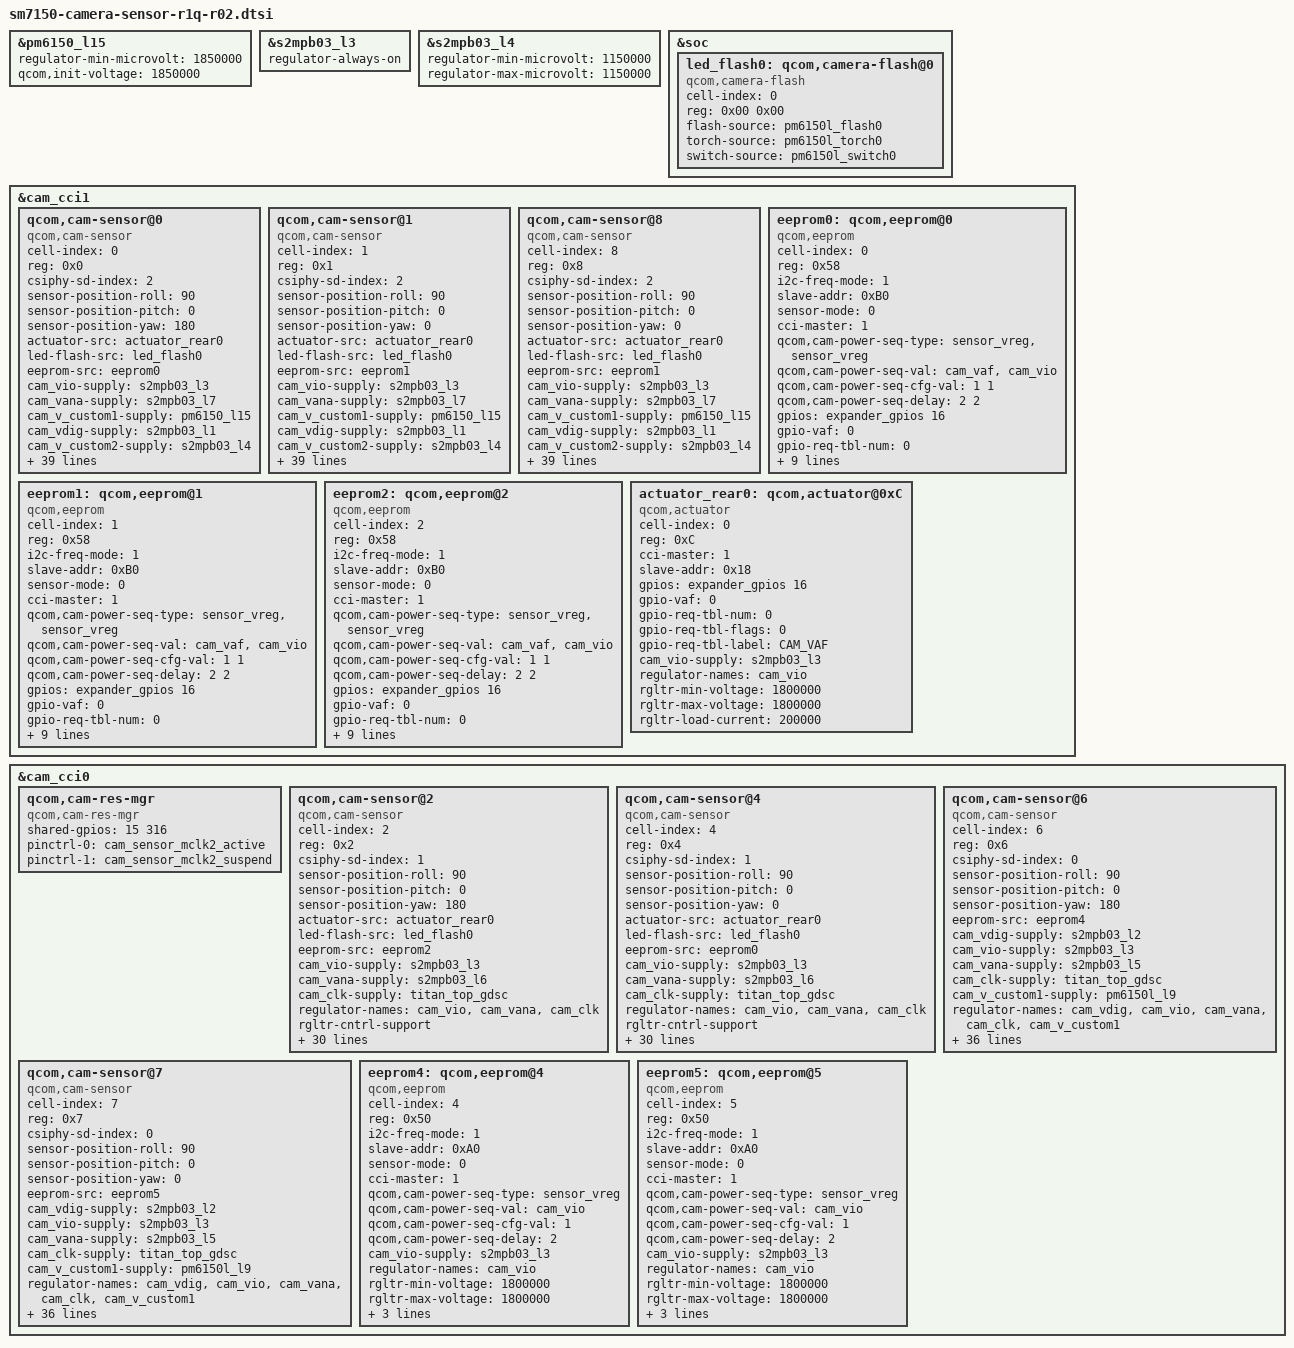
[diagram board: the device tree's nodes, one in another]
/*
 * Copyright (c) 2018, The Linux Foundation. All rights reserved.
 *
 * This program is free software; you can redistribute it and/or modify
 * it under the terms of the GNU General Public License version 2 and
 * only version 2 as published by the Free Software Foundation.
 *
 * This program is distributed in the hope that it will be useful,
 * but WITHOUT ANY WARRANTY; without even the implied warranty of
 * MERCHANTABILITY or FITNESS FOR A PARTICULAR PURPOSE.  See the
 * GNU General Public License for more details.
 */

&pm6150_l15 {
    regulator-min-microvolt = <1850000>;
    qcom,init-voltage = <1850000>;
};

&s2mpb03_l3 {
    regulator-always-on;
};

&s2mpb03_l4 {
    regulator-min-microvolt = <1150000>;
    regulator-max-microvolt = <1150000>;
};

&soc {
        led_flash0: qcom,camera-flash@0 {
              cell-index = <0>;
              reg = <0x00 0x00>;
              compatible = "qcom,camera-flash";
              flash-source = <&pm6150l_flash0>;
              torch-source = <&pm6150l_torch0>;
              switch-source = <&pm6150l_switch0>;		
              status = "ok";
        };
};

&cam_cci1 {
	qcom,cam-sensor@0 {
		cell-index = <0>;
		compatible = "qcom,cam-sensor";
		reg = <0x0>;
		csiphy-sd-index = <2>;
		sensor-position-roll = <90>;
		sensor-position-pitch = <0>;
		sensor-position-yaw = <180>;
		actuator-src = <&actuator_rear0>;
		led-flash-src = <&led_flash0>;
		eeprom-src = <&eeprom0>;

		// LDO
		cam_vio-supply = <&s2mpb03_l3>;
		cam_vana-supply = <&s2mpb03_l7>;
		cam_v_custom1-supply = <&pm6150_l15>;	// Analog 1.85
		cam_vdig-supply = <&s2mpb03_l1>;
		cam_v_custom2-supply = <&s2mpb03_l4>;	// Digital PLL 1.15
		cam_clk-supply = <&titan_top_gdsc>;
		regulator-names = "cam_vio", "cam_vana", "cam_v_custom1", "cam_vdig", "cam_v_custom2", "cam_clk";
		rgltr-cntrl-support;
		rgltr-min-voltage = <1800000 2900000 1850000 1100000 1150000 0>;
		rgltr-max-voltage = <1800000 2900000 1850000 1100000 1150000 0>;
		rgltr-load-current = <200000 200000 200000 200000 200000 0>;

		// GPIO
		gpio-no-mux = <0>;
		pinctrl-names = "cam_default", "cam_suspend";
		pinctrl-0 = <&cam_sensor_rear1_active>;
		pinctrl-1 = <&cam_sensor_rear1_suspend>;
		gpios = <&tlmm 15 0>,
			<&tlmm 33 0>,
			<&expander_gpios 16 0>;
		gpio-reset = <1>;
		gpio-vaf = <2>;
		gpio-req-tbl-num = <0 1 2>;
		gpio-req-tbl-flags = <1 0 0>;
		gpio-req-tbl-label = "CAMIF_MCLK2", "CAM_RESET1", "CAM_VAF";
		use-shared-clk;

		sensor-mode = <0>;
		cci-device = <1>;
		cci-master = <0>;
		status = "ok";
		clocks = <&clock_camcc CAM_CC_MCLK2_CLK>;
		clock-names = "cam_clk";
		clock-cntl-level = "turbo";
		clock-rates = <24000000>;
		cam,isp = <0>;                  // 0 : INT , 1 : EXT , 2 : SOC
		cam,cal_memory = <2>;           // 0 : N , 1 : FROM , 2 : EEPROM , 3 : OTP
		cam,read_version = <0>;         // 0 : SYSFS , 1 : CAMON
		cam,core_voltage = <0>;         // 0 : N , 1 : Y
		cam,upgrade = <0>;              // 0 : N , 1 : SYSFS , 2 : CAMON
		cam,fw_write = <0>;             // 0 : N , 1 : OS , 2 : SD , 3 : ALL
		cam,fw_dump = <0>;              // 0 : N , 1 : Y
		cam,companion_chip = <0>;       // 0 : N , 1 : Y
		cam,ois = <0>;                  // 0 : N , 1 : Y
		cam,dual_open = <0>;            // 0 : N , 1 : Y
		cam,valid = <1>;                // 0 : N , 1 : Y
	};

	qcom,cam-sensor@1 {
		cell-index = <1>;
		compatible = "qcom,cam-sensor";
		reg = <0x1>;
		csiphy-sd-index = <2>;
		sensor-position-roll = <90>;
		sensor-position-pitch = <0>;
		sensor-position-yaw = <0>;
		actuator-src = <&actuator_rear0>;
		led-flash-src = <&led_flash0>;
		eeprom-src = <&eeprom1>;

		// LDO
		cam_vio-supply = <&s2mpb03_l3>;
		cam_vana-supply = <&s2mpb03_l7>;
		cam_v_custom1-supply = <&pm6150_l15>;	// Analog 1.85
		cam_vdig-supply = <&s2mpb03_l1>;
		cam_v_custom2-supply = <&s2mpb03_l4>;	// Digital PLL 1.15
		cam_clk-supply = <&titan_top_gdsc>;
		regulator-names = "cam_vio", "cam_vana", "cam_v_custom1", "cam_vdig", "cam_v_custom2", "cam_clk";
		rgltr-cntrl-support;
		rgltr-min-voltage = <1800000 2900000 1850000 1100000 1150000 0>;
		rgltr-max-voltage = <1800000 2900000 1850000 1100000 1150000 0>;
		rgltr-load-current = <200000 200000 200000 200000 200000 0>;

		// GPIO
		gpio-no-mux = <0>;
		pinctrl-names = "cam_default", "cam_suspend";
		pinctrl-0 = <&cam_sensor_rear1_active>;
		pinctrl-1 = <&cam_sensor_rear1_suspend>;
		gpios = <&tlmm 15 0>,
			<&tlmm 33 0>,
			<&expander_gpios 16 0>;
		gpio-reset = <1>;
		gpio-vaf = <2>;
		gpio-req-tbl-num = <0 1 2>;
		gpio-req-tbl-flags = <1 0 0>;
		gpio-req-tbl-label = "CAMIF_MCLK2", "CAM_RESET1", "CAM_VAF";
		use-shared-clk;

		sensor-mode = <0>;
		cci-device = <1>;
		cci-master = <0>;
		status = "ok";
		clocks = <&clock_camcc CAM_CC_MCLK2_CLK>;
		clock-names = "cam_clk";
		clock-cntl-level = "turbo";
		clock-rates = <24000000>;
		cam,isp = <0>;                  // 0 : INT , 1 : EXT , 2 : SOC
		cam,cal_memory = <2>;           // 0 : N , 1 : FROM , 2 : EEPROM , 3 : OTP
		cam,read_version = <0>;         // 0 : SYSFS , 1 : CAMON
		cam,core_voltage = <0>;         // 0 : N , 1 : Y
		cam,upgrade = <0>;              // 0 : N , 1 : SYSFS , 2 : CAMON
		cam,fw_write = <0>;             // 0 : N , 1 : OS , 2 : SD , 3 : ALL
		cam,fw_dump = <0>;              // 0 : N , 1 : Y
		cam,companion_chip = <0>;       // 0 : N , 1 : Y
		cam,ois = <0>;                  // 0 : N , 1 : Y
		cam,dual_open = <0>;            // 0 : N , 1 : Y
		cam,valid = <1>;                // 0 : N , 1 : Y
	};

	qcom,cam-sensor@8 {
		cell-index = <8>;
		compatible = "qcom,cam-sensor";
		reg = <0x8>;
		csiphy-sd-index = <2>;
		sensor-position-roll = <90>;
		sensor-position-pitch = <0>;
		sensor-position-yaw = <0>;
		actuator-src = <&actuator_rear0>;
		led-flash-src = <&led_flash0>;
		eeprom-src = <&eeprom1>;

		// LDO
		cam_vio-supply = <&s2mpb03_l3>;
		cam_vana-supply = <&s2mpb03_l7>;
		cam_v_custom1-supply = <&pm6150_l15>;	// Analog 1.85
		cam_vdig-supply = <&s2mpb03_l1>;
		cam_v_custom2-supply = <&s2mpb03_l4>;	// Digital PLL 1.15
		cam_clk-supply = <&titan_top_gdsc>;
		regulator-names = "cam_vio", "cam_vana", "cam_v_custom1", "cam_vdig", "cam_v_custom2", "cam_clk";
		rgltr-cntrl-support;
		rgltr-min-voltage = <1800000 2900000 1850000 1100000 1150000 0>;
		rgltr-max-voltage = <1800000 2900000 1850000 1100000 1150000 0>;
		rgltr-load-current = <200000 200000 200000 200000 200000 0>;

		// GPIO
		gpio-no-mux = <0>;
		pinctrl-names = "cam_default", "cam_suspend";
		pinctrl-0 = <&cam_sensor_rear1_active>;
		pinctrl-1 = <&cam_sensor_rear1_suspend>;
		gpios = <&tlmm 15 0>,
			<&tlmm 33 0>,
			<&expander_gpios 16 0>;
		gpio-reset = <1>;
		gpio-vaf = <2>;
		gpio-req-tbl-num = <0 1 2>;
		gpio-req-tbl-flags = <1 0 0>;
		gpio-req-tbl-label = "CAMIF_MCLK2", "CAM_RESET1", "CAM_VAF";
		use-shared-clk;

		sensor-mode = <0>;
		cci-device = <1>;
		cci-master = <0>;
		status = "ok";
		clocks = <&clock_camcc CAM_CC_MCLK2_CLK>;
		clock-names = "cam_clk";
		clock-cntl-level = "turbo";
		clock-rates = <24000000>;
		cam,isp = <0>;                  // 0 : INT , 1 : EXT , 2 : SOC
		cam,cal_memory = <2>;           // 0 : N , 1 : FROM , 2 : EEPROM , 3 : OTP
		cam,read_version = <0>;         // 0 : SYSFS , 1 : CAMON
		cam,core_voltage = <0>;         // 0 : N , 1 : Y
		cam,upgrade = <0>;              // 0 : N , 1 : SYSFS , 2 : CAMON
		cam,fw_write = <0>;             // 0 : N , 1 : OS , 2 : SD , 3 : ALL
		cam,fw_dump = <0>;              // 0 : N , 1 : Y
		cam,companion_chip = <0>;       // 0 : N , 1 : Y
		cam,ois = <0>;                  // 0 : N , 1 : Y
		cam,dual_open = <0>;            // 0 : N , 1 : Y
		cam,valid = <1>;                // 0 : N , 1 : Y
	};
	
	eeprom0: qcom,eeprom@0 {
		cell-index = <0>;
		reg = <0x58>; //QUP use 0xB0
        	compatible = "qcom,eeprom";
        	i2c-freq-mode = <1>;
        	slave-addr = <0xB0>;
        	sensor-mode = <0>;
        	cci-master = <1>;

        	qcom,cam-power-seq-type = "sensor_vreg", "sensor_vreg";
        	qcom,cam-power-seq-val = "cam_vaf", "cam_vio";
        	qcom,cam-power-seq-cfg-val = <1 1>;
        	qcom,cam-power-seq-delay = <2 2>;

		gpios = <&expander_gpios 16 0>;
		gpio-vaf = <0>;
		gpio-req-tbl-num = <0>;
		gpio-req-tbl-flags = <0>;
		gpio-req-tbl-label = "CAM_VAF";

        	cam_vio-supply = <&s2mpb03_l3>;
        	regulator-names = "cam_vio";
		rgltr-min-voltage = <1800000>;
		rgltr-max-voltage = <1800000>;
			rgltr-load-current = <200000>;

			sensor-position = <0>;
			rgltr-cntrl-support;
		};

	eeprom1: qcom,eeprom@1 {
		cell-index = <1>;
		reg = <0x58>; //QUP use 0xB0
        	compatible = "qcom,eeprom";
        	i2c-freq-mode = <1>;
        	slave-addr = <0xB0>;
        	sensor-mode = <0>;
        	cci-master = <1>;

        	qcom,cam-power-seq-type = "sensor_vreg", "sensor_vreg";
        	qcom,cam-power-seq-val = "cam_vaf", "cam_vio";
        	qcom,cam-power-seq-cfg-val = <1 1>;
        	qcom,cam-power-seq-delay = <2 2>;

		gpios = <&expander_gpios 16 0>;
		gpio-vaf = <0>;
		gpio-req-tbl-num = <0>;
		gpio-req-tbl-flags = <0>;
		gpio-req-tbl-label = "CAM_VAF";

        	cam_vio-supply = <&s2mpb03_l3>;
        	regulator-names = "cam_vio";
		rgltr-min-voltage = <1800000>;
		rgltr-max-voltage = <1800000>;
		rgltr-load-current = <200000>;

		sensor-position = <0>;
		rgltr-cntrl-support;
	};

	eeprom2: qcom,eeprom@2 {
		cell-index = <2>;
		reg = <0x58>; //QUP use 0xB0
        	compatible = "qcom,eeprom";
        	i2c-freq-mode = <1>;
        	slave-addr = <0xB0>;
        	sensor-mode = <0>;
        	cci-master = <1>;

        	qcom,cam-power-seq-type = "sensor_vreg", "sensor_vreg";
        	qcom,cam-power-seq-val = "cam_vaf", "cam_vio";
        	qcom,cam-power-seq-cfg-val = <1 1>;
        	qcom,cam-power-seq-delay = <2 2>;

		gpios = <&expander_gpios 16 0>;
		gpio-vaf = <0>;
		gpio-req-tbl-num = <0>;
		gpio-req-tbl-flags = <0>;
		gpio-req-tbl-label = "CAM_VAF";

        	cam_vio-supply = <&s2mpb03_l3>;
        	regulator-names = "cam_vio";
		rgltr-min-voltage = <1800000>;
		rgltr-max-voltage = <1800000>;
		rgltr-load-current = <200000>;

		sensor-position = <0>;
		rgltr-cntrl-support;
	};

	actuator_rear0: qcom,actuator@0xC {
        	cell-index = <0>;
        	reg = <0xC>;
        	cci-master = <1>;
        	slave-addr = <0x18>;
        	compatible = "qcom,actuator";
        
		gpios = <&expander_gpios 16 0>;
		gpio-vaf = <0>;
		gpio-req-tbl-num = <0>;
		gpio-req-tbl-flags = <0>;
		gpio-req-tbl-label = "CAM_VAF";

        	cam_vio-supply = <&s2mpb03_l3>;
        	regulator-names = "cam_vio";
        	rgltr-min-voltage = <1800000>;
        	rgltr-max-voltage = <1800000>;
        	rgltr-load-current = <200000>;
	};
};

&cam_cci0 {
	qcom,cam-res-mgr {
		compatible = "qcom,cam-res-mgr";
		shared-gpios = <15 316>;
		pinctrl-names = "cam_res_mgr_default", "cam_res_mgr_suspend";
		status = "ok";
		pinctrl-0 = <&cam_sensor_mclk2_active>;
		pinctrl-1 = <&cam_sensor_mclk2_suspend>;
	};
	qcom,cam-sensor@2 {
		cell-index = <2>;
		compatible = "qcom,cam-sensor";
		reg = <0x2>;
		csiphy-sd-index = <1>;
		sensor-position-roll = <90>;
		sensor-position-pitch = <0>;
		sensor-position-yaw = <180>;
		actuator-src = <&actuator_rear0>;
		led-flash-src = <&led_flash0>;
		eeprom-src = <&eeprom2>;
		// LDO
		cam_vio-supply = <&s2mpb03_l3>;
		cam_vana-supply = <&s2mpb03_l6>;
		cam_clk-supply = <&titan_top_gdsc>;
		regulator-names = "cam_vio", "cam_vana", "cam_clk";
		rgltr-cntrl-support;
		rgltr-min-voltage = <1800000 2800000 0>;
		rgltr-max-voltage = <1800000 2800000 0>;
		rgltr-load-current = <200000 200000 0>;

		// GPIO
		gpio-no-mux = <0>;
		pinctrl-names = "cam_default", "cam_suspend";
		pinctrl-0 = <&cam_sensor_rear2_active>;
		pinctrl-1 = <&cam_sensor_rear2_suspend>;
		gpios = <&tlmm 15 0>,
			<&tlmm 67 0>,
			<&expander_gpios 17 0>;
		gpio-reset = <1>;
		gpio-vdig = <2>;
		gpio-req-tbl-num = <0 1 2>;
		gpio-req-tbl-flags = <1 0 0>;
		gpio-req-tbl-label = "CAMIF_MCLK2", "CAM_RESET2", "CAM_VDIG";
		use-shared-clk;

		sensor-mode = <0>;
		cci-master = <0>;
		status = "ok";
		clocks = <&clock_camcc CAM_CC_MCLK2_CLK>;
		clock-names = "cam_clk";
		clock-cntl-level = "turbo";
		clock-rates = <24000000>;

		cam,isp = <0>;                  // 0 : INT , 1 : EXT , 2 : SOC
		cam,cal_memory = <2>;           // 0 : N , 1 : FROM , 2 : EEPROM , 3 : OTP
		cam,read_version = <0>;         // 0 : SYSFS , 1 : CAMON
		cam,core_voltage = <0>;         // 0 : N , 1 : Y
		cam,upgrade = <0>;              // 0 : N , 1 : SYSFS , 2 : CAMON
		cam,fw_write = <0>;             // 0 : N , 1 : OS , 2 : SD , 3 : ALL
		cam,fw_dump = <0>;              // 0 : N , 1 : Y
		cam,companion_chip = <0>;       // 0 : N , 1 : Y
		cam,ois = <0>;                  // 0 : N , 1 : Y
		cam,dual_open = <0>;            // 0 : N , 1 : Y
		cam,valid = <1>;                // 0 : N , 1 : Y
	};
	qcom,cam-sensor@4 {
		cell-index = <4>;
		compatible = "qcom,cam-sensor";
		reg = <0x4>;
		csiphy-sd-index = <1>;
		sensor-position-roll = <90>;
		sensor-position-pitch = <0>;
		sensor-position-yaw = <0>;
		actuator-src = <&actuator_rear0>;
		led-flash-src = <&led_flash0>;
		eeprom-src = <&eeprom0>;
		// LDO
		cam_vio-supply = <&s2mpb03_l3>;
		cam_vana-supply = <&s2mpb03_l6>;
		cam_clk-supply = <&titan_top_gdsc>;
		regulator-names = "cam_vio", "cam_vana", "cam_clk";
		rgltr-cntrl-support;
		rgltr-min-voltage = <1800000 2800000 0>;
		rgltr-max-voltage = <1800000 2800000 0>;
		rgltr-load-current = <200000 200000 0>;

		// GPIO
		gpio-no-mux = <0>;
		pinctrl-names = "cam_default", "cam_suspend";
		pinctrl-0 = <&cam_sensor_rear2_active>;
		pinctrl-1 = <&cam_sensor_rear2_suspend>;
		gpios = <&tlmm 15 0>,
			<&tlmm 67 0>,
			<&expander_gpios 17 0>;
		gpio-reset = <1>;
		gpio-vdig = <2>;
		gpio-req-tbl-num = <0 1 2>;
		gpio-req-tbl-flags = <1 0 0>;
		gpio-req-tbl-label = "CAMIF_MCLK2", "CAM_RESET2", "CAM_VDIG";
		use-shared-clk;

		sensor-mode = <0>;
		cci-master = <0>;
		status = "ok";
		clocks = <&clock_camcc CAM_CC_MCLK2_CLK>;
		clock-names = "cam_clk";
		clock-cntl-level = "turbo";
		clock-rates = <24000000>;

		cam,isp = <0>;                  // 0 : INT , 1 : EXT , 2 : SOC
		cam,cal_memory = <2>;           // 0 : N , 1 : FROM , 2 : EEPROM , 3 : OTP
		cam,read_version = <0>;         // 0 : SYSFS , 1 : CAMON
		cam,core_voltage = <0>;         // 0 : N , 1 : Y
		cam,upgrade = <0>;              // 0 : N , 1 : SYSFS , 2 : CAMON
		cam,fw_write = <0>;             // 0 : N , 1 : OS , 2 : SD , 3 : ALL
		cam,fw_dump = <0>;              // 0 : N , 1 : Y
		cam,companion_chip = <0>;       // 0 : N , 1 : Y
		cam,ois = <0>;                  // 0 : N , 1 : Y
		cam,dual_open = <0>;            // 0 : N , 1 : Y
		cam,valid = <1>;                // 0 : N , 1 : Y
	};
 	qcom,cam-sensor@6 {
		cell-index = <6>; // REAR TOF
		compatible = "qcom,cam-sensor";
		reg = <0x6>;
		csiphy-sd-index = <0>;
		sensor-position-roll = <90>;
		sensor-position-pitch = <0>;
		sensor-position-yaw = <180>;
		eeprom-src = <&eeprom4>;
		cam_vdig-supply = <&s2mpb03_l2>;
		cam_vio-supply = <&s2mpb03_l3>;
		cam_vana-supply = <&s2mpb03_l5>;
		cam_clk-supply = <&titan_top_gdsc>;
		cam_v_custom1-supply = <&pm6150l_l9>;
		regulator-names = "cam_vdig", "cam_vio", "cam_vana", "cam_clk", "cam_v_custom1";
		rgltr-cntrl-support;
		rgltr-min-voltage = <1200000 1800000 2700000 0 3300000>;
		rgltr-max-voltage = <1200000 1800000 2700000 0 3300000>;
		rgltr-load-current = <200000 200000 200000 0 200000>;
		gpio-no-mux = <0>;
		pinctrl-names = "cam_default", "cam_suspend";
		pinctrl-0 = <&cam_sensor_mclk0_active
			&cam_sensor_tof_active>;
		pinctrl-1 = <&cam_sensor_mclk0_suspend
			&cam_sensor_tof_suspend>;
		gpios = <&tlmm 13 0>,  // MCLK
			<&tlmm 23 0>, // TOF RESET
			<&tlmm 24 0>; // TOF DCDC ENABLE

		gpio-reset = <1>;
		gpio-custom1 = <2>;
		gpio-req-tbl-num = <0 1 2 >;
		gpio-req-tbl-flags = <1 0 0 >;
		gpio-req-tbl-label = "CAMIF_MCLK0",
					"CAM_RESET3",
					"TOF_DCDC_ENABLE";
        sensor-mode = <0>;
		cci-master = <0>;
		cci-device = <0>;
		status = "ok";
		clocks = <&clock_camcc CAM_CC_MCLK0_CLK>;
		clock-names = "cam_clk";
		clock-cntl-level = "turbo";
		clock-rates = <24000000>;

		cam,isp = <0>;                  // 0 : INT , 1 : EXT , 2 : SOC
		cam,cal_memory = <0>;           // 0 : N , 1 : FROM , 2 : EEPROM , 3 : OTP
		cam,read_version = <0>;         // 0 : SYSFS , 1 : CAMON
		cam,core_voltage = <0>;         // 0 : N , 1 : Y
		cam,upgrade = <0>;              // 0 : N , 1 : SYSFS , 2 : CAMON
		cam,fw_write = <0>;             // 0 : N , 1 : OS , 2 : SD , 3 : ALL
		cam,fw_dump = <0>;              // 0 : N , 1 : Y
		cam,companion_chip = <0>;       // 0 : N , 1 : Y
		cam,ois = <0>;                  // 0 : N , 1 : Y
		cam,dual_open = <0>;            // 0 : N , 1 : Y
		cam,valid = <1>;                // 0 : N , 1 : Y
	};

 	qcom,cam-sensor@7 {
		cell-index = <7>; // REAR TOF
		compatible = "qcom,cam-sensor";
		reg = <0x7>;
		csiphy-sd-index = <0>;
		sensor-position-roll = <90>;
		sensor-position-pitch = <0>;
		sensor-position-yaw = <0>;
		eeprom-src = <&eeprom5>;
		cam_vdig-supply = <&s2mpb03_l2>;
		cam_vio-supply = <&s2mpb03_l3>;
		cam_vana-supply = <&s2mpb03_l5>;
		cam_clk-supply = <&titan_top_gdsc>;
		cam_v_custom1-supply = <&pm6150l_l9>;
		regulator-names = "cam_vdig", "cam_vio", "cam_vana", "cam_clk", "cam_v_custom1";
		rgltr-cntrl-support;
		rgltr-min-voltage = <1200000 1800000 2700000 0 3300000>;
		rgltr-max-voltage = <1200000 1800000 2700000 0 3300000>;
		rgltr-load-current = <200000 200000 200000 0 200000>;
		gpio-no-mux = <0>;
		pinctrl-names = "cam_default", "cam_suspend";
		pinctrl-0 = <&cam_sensor_mclk0_active
			&cam_sensor_tof_active>;
		pinctrl-1 = <&cam_sensor_mclk0_suspend
			&cam_sensor_tof_suspend>;
		gpios = <&tlmm 13 0>,  // MCLK
			<&tlmm 23 0>, // TOF RESET
			<&tlmm 24 0>; // TOF DCDC ENABLE

		gpio-reset = <1>;
		gpio-custom1 = <2>;
		gpio-req-tbl-num = <0 1 2 >;
		gpio-req-tbl-flags = <1 0 0 >;
		gpio-req-tbl-label = "CAMIF_MCLK0",
					"CAM_RESET3",
					"TOF_DCDC_ENABLE";
        sensor-mode = <0>;
		cci-master = <0>;
		cci-device = <0>;
		status = "ok";
		clocks = <&clock_camcc CAM_CC_MCLK0_CLK>;
		clock-names = "cam_clk";
		clock-cntl-level = "turbo";
		clock-rates = <24000000>;

		cam,isp = <0>;                  // 0 : INT , 1 : EXT , 2 : SOC
		cam,cal_memory = <0>;           // 0 : N , 1 : FROM , 2 : EEPROM , 3 : OTP
		cam,read_version = <0>;         // 0 : SYSFS , 1 : CAMON
		cam,core_voltage = <0>;         // 0 : N , 1 : Y
		cam,upgrade = <0>;              // 0 : N , 1 : SYSFS , 2 : CAMON
		cam,fw_write = <0>;             // 0 : N , 1 : OS , 2 : SD , 3 : ALL
		cam,fw_dump = <0>;              // 0 : N , 1 : Y
		cam,companion_chip = <0>;       // 0 : N , 1 : Y
		cam,ois = <0>;                  // 0 : N , 1 : Y
		cam,dual_open = <0>;            // 0 : N , 1 : Y
		cam,valid = <1>;                // 0 : N , 1 : Y
	};

	eeprom4: qcom,eeprom@4 {
                cell-index = <4>;
                reg = <0x50>;//QUP use 0xA0
                compatible = "qcom,eeprom";
                i2c-freq-mode = <1>;
                slave-addr = <0xA0>;
                sensor-mode = <0>;
                cci-master = <1>;

                qcom,cam-power-seq-type = "sensor_vreg";
                qcom,cam-power-seq-val = "cam_vio";
                qcom,cam-power-seq-cfg-val = <1>;
                qcom,cam-power-seq-delay = <2>;

                cam_vio-supply = <&s2mpb03_l3>;
                regulator-names = "cam_vio";
                rgltr-min-voltage = <1800000>;
                rgltr-max-voltage = <1800000>;
                rgltr-load-current = <200000>;

                sensor-position = <1>;
                rgltr-cntrl-support;
	};

	eeprom5: qcom,eeprom@5 {
                cell-index = <5>;
                reg = <0x50>;//QUP use 0xA0
                compatible = "qcom,eeprom";
                i2c-freq-mode = <1>;
                slave-addr = <0xA0>;
                sensor-mode = <0>;
                cci-master = <1>;

                qcom,cam-power-seq-type = "sensor_vreg";
                qcom,cam-power-seq-val = "cam_vio";
                qcom,cam-power-seq-cfg-val = <1>;
                qcom,cam-power-seq-delay = <2>;

                cam_vio-supply = <&s2mpb03_l3>;
                regulator-names = "cam_vio";
                rgltr-min-voltage = <1800000>;
                rgltr-max-voltage = <1800000>;
                rgltr-load-current = <200000>;

                sensor-position = <1>;
                rgltr-cntrl-support;
	};
};
